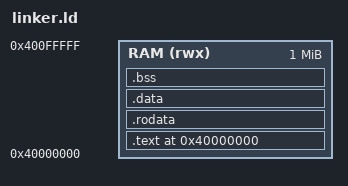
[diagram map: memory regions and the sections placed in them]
ENTRY(_start)

MEMORY
{
    RAM (rwx) : ORIGIN = 0x40000000, LENGTH = 1M
}

SECTIONS
{
    . = 0x40000000;

    .text : {
        KEEP(*(.text.boot))
        *(.text*)
    } > RAM

    .rodata : {
        *(.rodata*)
    } > RAM

    .data : {
        *(.data*)
    } > RAM

    .bss : {
        __bss_start = .;
        *(.bss*)
        *(COMMON)
        __bss_end = .;
    } > RAM

    . = ORIGIN(RAM) + LENGTH(RAM);
    _stack_top = .;
}
